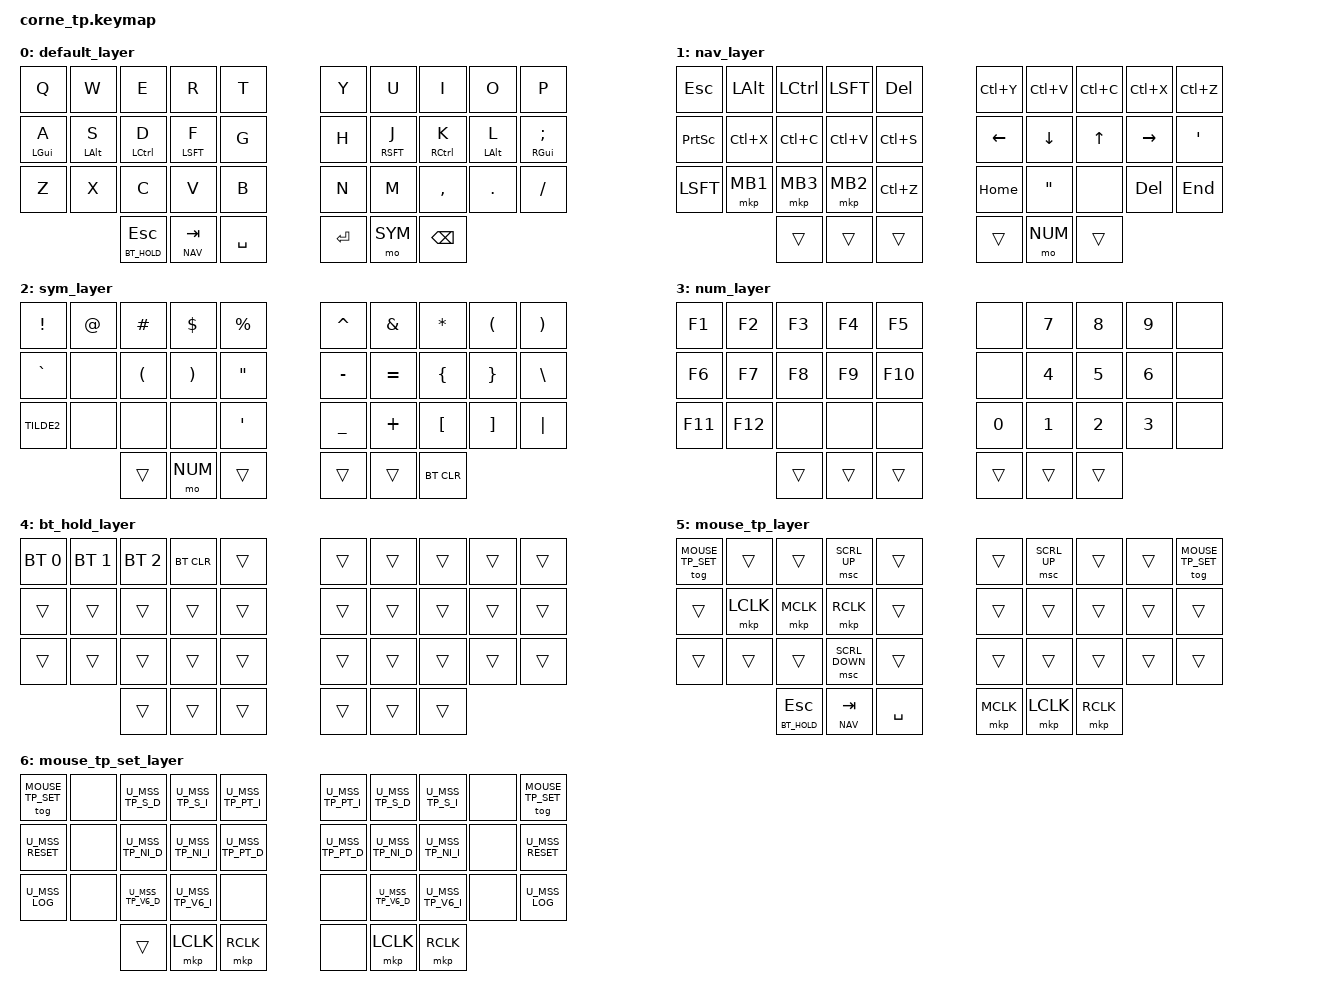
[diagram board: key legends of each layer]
#include <behaviors.dtsi>
#include <dt-bindings/zmk/keys.h>
#include <dt-bindings/zmk/bt.h>

#define BASE 0
#define NAV  1
#define SYM  2
#define NUM  3
#define BT_HOLD  4
#define MOUSE_TP 5
#define MOUSE_TP_SET 6

#define HAS_MOUSE_KEYS
#define HAS_MOUSE_TP

#ifdef HAS_MOUSE_KEYS
  #include <dt-bindings/zmk/mouse.h>
  #include <behaviors/mouse_keys.dtsi>
#endif

#ifdef HAS_MOUSE_TP
  #include "include/mouse_tp.dtsi"
#endif

#ifdef HAS_MOUSE_TP
  #define U_TOG_TP_SET &tog MOUSE_TP_SET
#else
  #define U_TOG_TP_SET &none
#endif

/ {

    chosen {
        zmk,matrix_transform = &five_column_transform;
    };

    behaviors {
        // Homerow mod: balanced flavor, 200 ms tapping term, 150 ms prior-idle
        // (mirrors QMK TAPPING_TERM 200 / FLOW_TAP_TERM 150 / QUICK_TAP_TERM 0)
        hm: homerow_mods {
            compatible = "zmk,behavior-hold-tap";
            #binding-cells = <2>;
            tapping-term-ms = <200>;
            quick-tap-ms = <0>;
            require-prior-idle-ms = <150>;
            flavor = "balanced";
            bindings = <&kp>, <&kp>;
        };
    };

    keymap {
        compatible = "zmk,keymap";

        // ─── Layer 0 ── BASE ─────────────────────────────────────────────────
        // ┌───────┬───────┬───────┬───────┬───────┐   ┌───────┬───────┬───────┬───────┬───────┐
        // │   Q   │   W   │   E   │   R   │   T   │   │   Y   │   U   │   I   │   O   │   P   │
        // ├───────┼───────┼───────┼───────┼───────┤   ├───────┼───────┼───────┼───────┼───────┤
        // │ GUI/A │ ALT/S │ CTL/D │ SFT/F │   G   │   │   H   │ SFT/J │ CTL/K │ ALT/L │ GUI/; │
        // ├───────┼───────┼───────┼───────┼───────┤   ├───────┼───────┼───────┼───────┼───────┤
        // │   Z   │   X   │   C   │   V   │   B   │   │   N   │   M   │   ,   │   .   │   /   │
        // └───────┴───────┴───┬───┴───┬───┴───┬───┘   └───┬───┴───┬───┴───┬───┴───────┴───────┘
        //                     │  ESC  │NAV/TAB│  SPC  │   │  ENT  │  SYM  │ BSPC  │
        //                     └───────┴───────┴───────┘   └───────┴───────┴───────┘
        default_layer {
            bindings = <
                &kp Q       &kp W       &kp E       &kp R       &kp T           &kp Y      &kp U       &kp I       &kp O       &kp P
                &hm LGUI A  &hm LALT S  &hm LCTL D  &hm LSFT F  &kp G           &kp H      &hm RSFT J  &hm RCTL K  &hm LALT L  &hm RGUI SEMI
                &kp Z       &kp X       &kp C       &kp V       &kp B           &kp N      &kp M       &kp COMMA   &kp DOT     &kp FSLH
                                        &lt BT_HOLD ESC &lt NAV TAB &kp SPACE       &kp RET    &mo SYM     &kp BSPC
            >;
        };

        // ─── Layer 1 ── NAV ──────────────────────────────────────────────────
        // ┌───────┬───────┬───────┬───────┬───────┐   ┌───────┬───────┬───────┬───────┬───────┐
        // │  ESC  │ ALT   │ CTL   │ SFT   │  DEL  │   │ REDO  │ PASTE │ COPY  │  CUT  │ UNDO  │
        // ├───────┼───────┼───────┼───────┼───────┤   ├───────┼───────┼───────┼───────┼───────┤
        // │Pr.Scr │ C(X)  │ C(C)  │ C(V)  │ C(S)  │   │ LEFT  │ DOWN  │  UP   │ RIGHT │   '   │
        // ├───────┼───────┼───────┼───────┼───────┤   ├───────┼───────┼───────┼───────┼───────┤
        // │ SHIFT │ BTN1  │ BTN3  │ BTN2  │ C(Z)  │   │ HOME  │   "   │  ---  │  DEL  │  END  │
        // └───────┴───────┴───┬───┴───┬───┴───┬───┘   └───┬───┴───┬───┴───┬───┴───────┴───────┘
        //                     │ TRNS  │ TRNS  │ TRNS  │   │ TRNS  │  NUM  │ TRNS  │
        //                     └───────┴───────┴───────┘   └───────┴───────┴───────┘
        nav_layer {
            bindings = <
                &kp ESC     &kp LALT &kp LCTL     &kp LSFT      &kp DEL         &kp LC(Y)  &kp LC(V)   &kp LC(C)   &kp LC(X)   &kp LC(Z)
                &kp PRINTSCREEN &kp LC(X)   &kp LC(C)   &kp LC(V)   &kp LC(S)       &kp LEFT   &kp DOWN    &kp UP      &kp RIGHT   &kp SQT
                &kp LSFT    &mkp MB1    &mkp MB3    &mkp MB2    &kp LC(Z)       &kp HOME   &kp DQT     &none       &kp DEL     &kp END
                                        &trans      &trans      &trans          &trans     &mo NUM     &trans
            >;
        };

        // ─── Layer 2 ── SYM ──────────────────────────────────────────────────
        // ┌───────┬───────┬───────┬───────┬───────┐   ┌───────┬───────┬───────┬───────┬───────┐
        // │   !   │   @   │   #   │   $   │   %   │   │   ^   │   &   │   *   │   (   │   )   │
        // ├───────┼───────┼───────┼───────┼───────┤   ├───────┼───────┼───────┼───────┼───────┤
        // │ GRAVE │   --- │   (   │  )    │   "   │   │   -   │   =   │   {   │   }   │   \   │
        // ├───────┼───────┼───────┼───────┼───────┤   ├───────┼───────┼───────┼───────┼───────┤
        // │ Tilde │  ---  │  ---  │  ---  │    '  │   │   _   │   +   │   [   │   ]   │   |   │
        // └───────┴───────┴───┬───┴───┬───┴───┬───┘   └───┬───┴───┬───┴───┬───┴───────┴───────┘
        //                     │ TRNS  │  NUM  │ TRNS  │   │ TRNS  │ TRNS  │   `   │
        //                     └───────┴───────┴───────┘   └───────┴───────┴───────┘
        sym_layer {
            bindings = <
                &kp EXCL    &kp AT      &kp HASH    &kp DLLR    &kp PRCNT       &kp CARET  &kp AMPS    &kp ASTRK   &kp LPAR    &kp RPAR
                &kp GRAVE   &none       &kp LPAR    &kp RPAR    &kp DQT         &kp MINUS  &kp EQUAL   &kp LBRC    &kp RBRC    &kp BSLH
                &kp TILDE2  &none       &none       &none       &kp SQT           &kp UNDER  &kp PLUS    &kp LBKT    &kp RBKT    &kp PIPE
                                        &trans      &mo NUM     &trans          &trans     &trans      &bt BT_CLR
            >;
        };

        // ─── Layer 3 ── NUM ──────────────────────────────────────────────────
        // ┌───────┬───────┬───────┬───────┬───────┐   ┌───────┬───────┬───────┬───────┬───────┐
        // │  ---  │  ---  │  ---  │  ---  │  ---  │   │  ---  │   7   │   8   │   9   │  ---  │
        // ├───────┼───────┼───────┼───────┼───────┤   ├───────┼───────┼───────┼───────┼───────┤
        // │  ---  │  ---  │  ---  │  ---  │  ---  │   │  ---  │   4   │   5   │   6   │  ---  │
        // ├───────┼───────┼───────┼───────┼───────┤   ├───────┼───────┼───────┼───────┼───────┤
        // │  ---  │  ---  │  ---  │  ---  │  ---  │   │   0   │   1   │   2   │   3   │  ---  │
        // └───────┴───────┴───┬───┴───┬───┴───┬───┘   └───┬───┴───┬───┴───┬───┴───────┴───────┘
        //                     │ TRNS  │ TRNS  │ TRNS  │   │ TRNS  │ TRNS  │ TRNS  │
        //                     └───────┴───────┴───────┘   └───────┴───────┴───────┘
        num_layer {
            bindings = <
                &kp F1       &kp F2       &kp F3       &kp F4       &kp F5       &none      &kp N7      &kp N8      &kp N9      &none
                &kp F6       &kp F7       &kp F8       &kp F9       &kp F10       &none      &kp N4      &kp N5      &kp N6      &none
                &kp F11      &kp F12       &none        &none        &none       &kp N0     &kp N1      &kp N2      &kp N3      &none
                                          &trans       &trans       &trans      &trans     &trans      &trans
            >;
        };

        // ─── Layer 4 ── BT_HOLD ──────────────────────────────────────────────
        // ┌───────┬───────┬───────┬───────┬───────┐   ┌───────┬───────┬───────┬───────┬───────┐
        // │ BT 0  │ BT 1  │ BT 2  │BT CLR │  ---  │   │  ---  │  ---  │  ---  │  ---  │  ---  │
        // ├───────┼───────┼───────┼───────┼───────┤   ├───────┼───────┼───────┼───────┼───────┤
        // │  ---  │  ---  │  ---  │  ---  │  ---  │   │  ---  │  ---  │  ---  │  ---  │  ---  │
        // ├───────┼───────┼───────┼───────┼───────┤   ├───────┼───────┼───────┼───────┼───────┤
        // │  ---  │  ---  │  ---  │  ---  │  ---  │   │  ---  │  ---  │  ---  │  ---  │  ---  │
        // └───────┴───────┴───┬───┴───┬───┴───┬───┘   └───┬───┴───┬───┴───┬───┴───────┴───────┘
        //                     │(hold) │ TRNS  │ TRNS  │   │ TRNS  │ TRNS  │ TRNS  │
        //                     └───────┴───────┴───────┘   └───────┴───────┴───────┘
        bt_hold_layer {
            bindings = <
                &bt BT_SEL 0 &bt BT_SEL 1 &bt BT_SEL 2 &bt BT_CLR  &trans      &trans      &trans      &trans      &trans      &trans
                &trans        &trans        &trans        &trans        &trans      &trans      &trans      &trans      &trans      &trans
                &trans        &trans        &trans        &trans        &trans      &trans      &trans      &trans      &trans      &trans
                                          &trans        &trans        &trans          &trans      &trans      &trans
            >;
        };

#ifdef HAS_MOUSE_TP

        // ─── Layer 5 ── MOUSE_TP ─────────────────────────────────────────────
        // Auto-activated by TrackPoint movement (via layer-toggle in mouse_tp.dtsi).
        // Thumb cluster gives easy access to clicks without holding any modifier.
        // ┌───────┬───────┬───────┬───────┬───────┐   ┌───────┬───────┬───────┬───────┬───────┐
        // │TP SET │ ---   │ ---   │ SCLU  │ ---   │   │ ---   │ SCLU  │ ---   │ ---   │TP SET │
        // ├───────┼───────┼───────┼───────┼───────┤   ├───────┼───────┼───────┼───────┼───────┤
        // │ ---   │ LCK   │ MID   │ RCK   │ ---   │   │ ---   │ ---   │ ---   │ ---   │ ---   │
        // ├───────┼───────┼───────┼───────┼───────┤   ├───────┼───────┼───────┼───────┼───────┤
        // │ ---   │ ---   │ ---   │ SCLD  │ ---   │   │ ---   │ ---   │ ---   │ ---   │ ---   │
        // └───────┴───────┴─┬─────┴─┬─────┴─┬─────┘   └─┬─────┴─┬─────┴─┬─────┴───────┴───────┘
        //                   │ ESC  │NAV/TAB│  SPC  │   │  MID  │  LCK  │  RCK  │
        mouse_tp_layer {
            bindings = <
                U_TOG_TP_SET &trans       &trans       &msc SCRL_UP   &trans          &trans      &msc SCRL_UP &trans       &trans       U_TOG_TP_SET
                &trans       &mkp LCLK       &mkp MCLK       &mkp RCLK         &trans          &trans      &trans       &trans       &trans       &trans
                &trans       &trans       &trans       &msc SCRL_DOWN &trans          &trans      &trans       &trans       &trans       &trans
                                &lt BT_HOLD ESC &lt NAV TAB &kp SPACE       &mkp MCLK   &mkp LCLK   &mkp RCLK
            >;
        };

        // ─── Layer 6 ── MOUSE_TP_SET ─────────────────────────────────────────
        // Toggled by U_TOG_TP_SET. Adjust TrackPoint sensitivity at runtime.
        // ┌───────┬───────┬───────┬───────┬───────┐   ┌───────┬───────┬───────┬───────┬───────┐
        // │TP SET │ ---   │ S DWN │ S UP  │ PT UP │   │ PT UP │ S DWN │ S UP  │ ---   │TP SET │
        // ├───────┼───────┼───────┼───────┼───────┤   ├───────┼───────┼───────┼───────┼───────┤
        // │ RESET │ ---   │NI DWN │ NI UP │ PT DN │   │ PT DN │NI DWN │ NI UP │ ---   │ RESET │
        // ├───────┼───────┼───────┼───────┼───────┤   ├───────┼───────┼───────┼───────┼───────┤
        // │  LOG  │ ---   │ V6 DN │ V6 UP │ ---   │   │ ---   │ V6 DN │ V6 UP │ ---   │  LOG  │
        // └───────┴───────┴─┬─────┴─┬─────┴─┬─────┘   └─┬─────┴─┬─────┴─┬─────┴───────┴───────┘
        //                   │ ---   │  LCK  │  RCK  │   │ ---   │  LCK  │  RCK  │
        mouse_tp_set_layer {
            bindings = <
                U_TOG_TP_SET &none        U_MSS_TP_S_D  U_MSS_TP_S_I  U_MSS_TP_PT_I   U_MSS_TP_PT_I U_MSS_TP_S_D  U_MSS_TP_S_I  &none        U_TOG_TP_SET
                U_MSS_RESET  &none        U_MSS_TP_NI_D U_MSS_TP_NI_I U_MSS_TP_PT_D   U_MSS_TP_PT_D U_MSS_TP_NI_D U_MSS_TP_NI_I &none        U_MSS_RESET
                U_MSS_LOG    &none        U_MSS_TP_V6_D U_MSS_TP_V6_I &none           &none         U_MSS_TP_V6_D U_MSS_TP_V6_I &none        U_MSS_LOG
                                          &trans        &mkp LCLK     &mkp RCLK        &none         &mkp LCLK     &mkp RCLK
            >;
        };

#endif  // HAS_MOUSE_TP

    };
};
